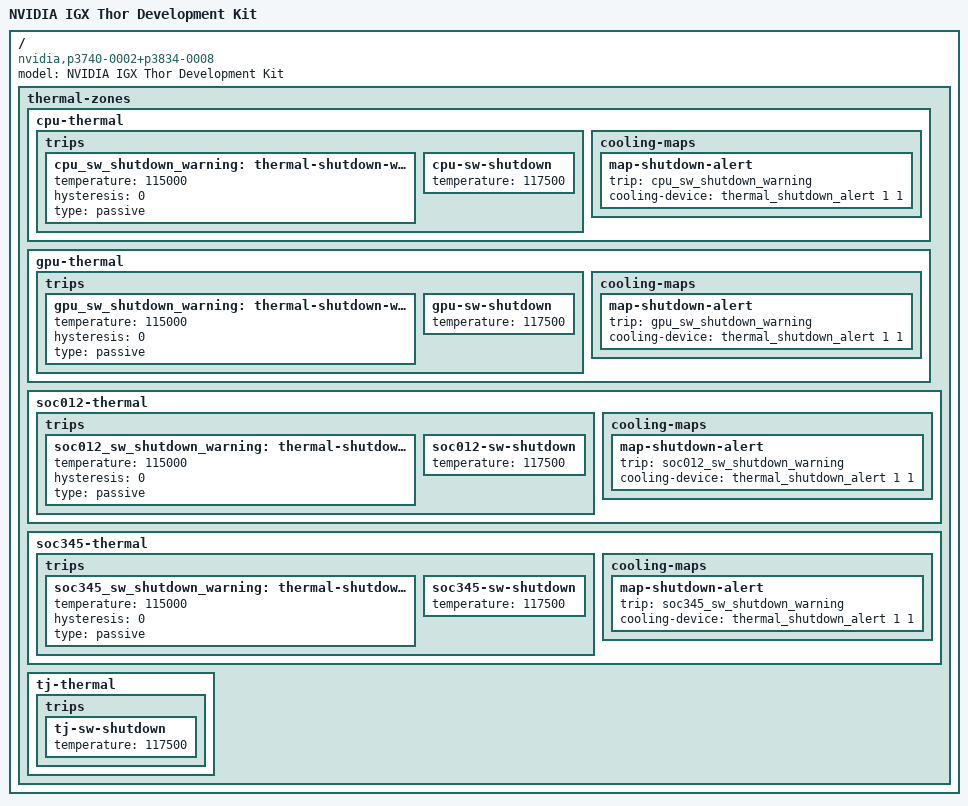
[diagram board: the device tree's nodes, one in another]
// SPDX-License-Identifier: GPL-2.0-only
// SPDX-FileCopyrightText: Copyright (c) 2024-2025, NVIDIA CORPORATION & AFFILIATES.  All rights reserved.

//
// ### WARNING ###
// DO NOT ENABLE TPM DEVICE IN THE IGX DEVICE TREE
// IF NEEDED, PLEASE REACH OUT TO THE NVIDIA IGX PRODUCT TEAM
// IT IS ILLEGAL TO ENABLE TPM FOR DEVICE GETTING SHIPPED TO CHINA

/dts-v1/;

#include "tegra264-p3834-0008.dtsi"
#include "tegra264-p3740-0002.dtsi"
#include "nv-soc/tegra264-soc-thermal-slowdown-disable.dtsi"

/ {
	model = "NVIDIA IGX Thor Development Kit";
	compatible = "nvidia,p3740-0002+p3834-0008", "nvidia,p3834-0008", "nvidia,tegra264";

	thermal-zones {
		cpu-thermal {
			trips {
				cpu_sw_shutdown_warning: thermal-shutdown-warning {
					temperature = <115000>;
					hysteresis = <0>;
					type = "passive";
				};

				cpu-sw-shutdown {
					temperature = <117500>;
				};
			};

			cooling-maps {
				map-shutdown-alert {
					trip = <&cpu_sw_shutdown_warning>;
					cooling-device = <&thermal_shutdown_alert 1 1>;
				};
			};
		};

		gpu-thermal {
			trips {
				gpu_sw_shutdown_warning: thermal-shutdown-warning {
					temperature = <115000>;
					hysteresis = <0>;
					type = "passive";
				};

				gpu-sw-shutdown {
					temperature = <117500>;
				};
			};

			cooling-maps {
				map-shutdown-alert {
					trip = <&gpu_sw_shutdown_warning>;
					cooling-device = <&thermal_shutdown_alert 1 1>;
				};
			};
		};

		soc012-thermal {
			trips {
				soc012_sw_shutdown_warning: thermal-shutdown-warning {
					temperature = <115000>;
					hysteresis = <0>;
					type = "passive";
				};

				soc012-sw-shutdown {
					temperature = <117500>;
				};
			};

			cooling-maps {
				map-shutdown-alert {
					trip = <&soc012_sw_shutdown_warning>;
					cooling-device = <&thermal_shutdown_alert 1 1>;
				};
			};
		};

		soc345-thermal {
			trips {
				soc345_sw_shutdown_warning: thermal-shutdown-warning {
					temperature = <115000>;
					hysteresis = <0>;
					type = "passive";
				};

				soc345-sw-shutdown {
					temperature = <117500>;
				};
			};

			cooling-maps {
				map-shutdown-alert {
					trip = <&soc345_sw_shutdown_warning>;
					cooling-device = <&thermal_shutdown_alert 1 1>;
				};
			};
		};

		tj-thermal {
			trips {
				tj-sw-shutdown {
					temperature = <117500>;
				};
			};
		};
	};
};
